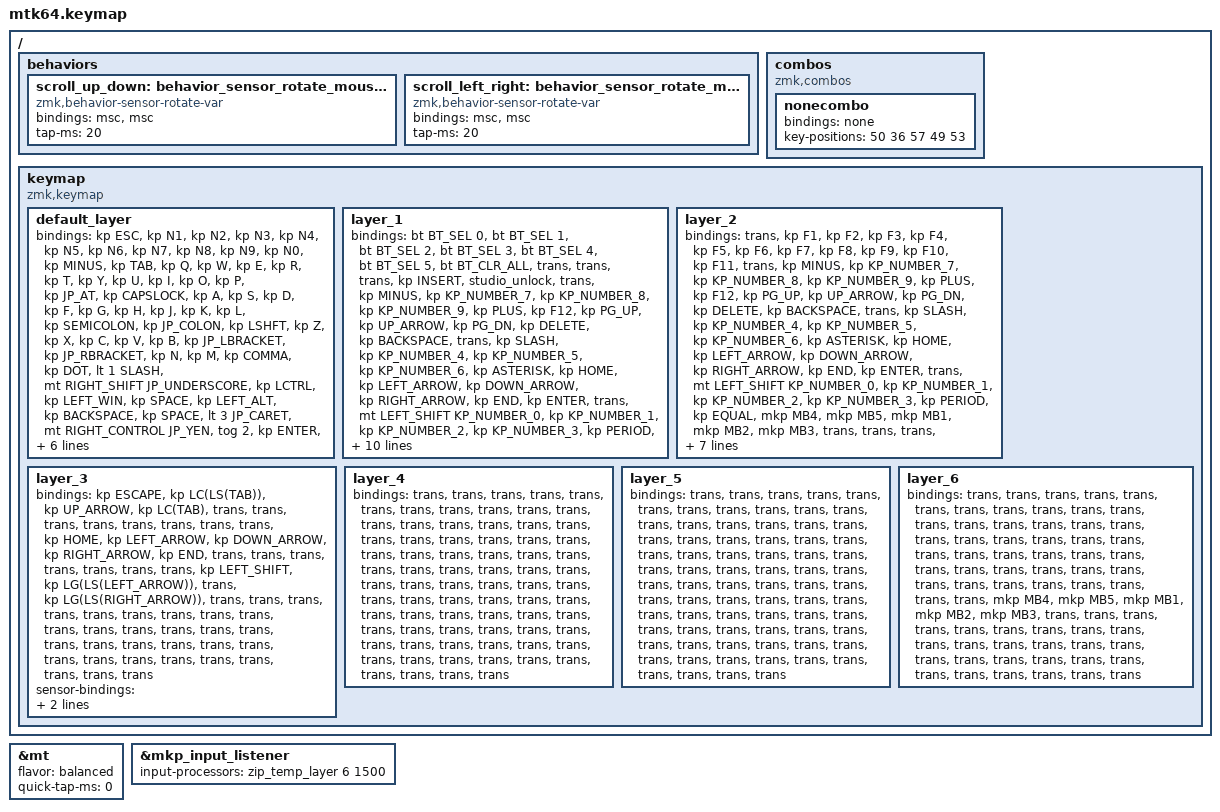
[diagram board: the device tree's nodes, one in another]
#include <input/processors.dtsi>
#include <behaviors.dtsi>
#include <dt-bindings/zmk/bt.h>
#include <dt-bindings/zmk/keys.h>
#include <dt-bindings/zmk/pointing.h>
#include "keycode_japanese.h"

// スクロール量の設定

#define ZMK_POINTING_DEFAULT_SCRL_VAL 100

// OS設定を日本語キーボードのまま使用するための変換定義

#define JP_DQUOTE       AT                // "
#define JP_AMPERSAND    CARET             // &
#define JP_QUOTE        AMPERSAND         // '
#define JP_EQUAL        UNDER             // =
#define JP_CARET        EQUAL             // ^
#define JP_YEN          0x89              // ¥
#define JP_PLUS         COLON             // +
#define JP_TILDE        PLUS              // ~
#define JP_PIPE         LS(0x89)          // |
#define JP_AT           LEFT_BRACKET      // @
#define JP_COLON        SINGLE_QUOTE      // :
#define JP_ASTERISK     DOUBLE_QUOTES     // *
#define JP_BACKQUOTE    LEFT_BRACE        // `
#define JP_UNDERSCORE   LS(0x87)          // _
#define JP_LBRACKET     RIGHT_BRACKET     // [
#define JP_RBRACKET     BACKSLASH         // ]
#define JP_LPAREN       ASTERISK          // (
#define JP_RPAREN       LEFT_PARENTHESIS  // )
#define JP_LBRACE       RIGHT_BRACE       // {
#define JP_RBRACE       PIPE              // }
#define JP_KANA         LANGUAGE_1        // かな
#define JP_EISU         LANGUAGE_2        // 英数
#define JP_HANZEN       GRAVE             // 半角/全角

&mt {
    flavor = "balanced";
    quick-tap-ms = <0>;
};

&mkp_input_listener { input-processors = <&zip_temp_layer 6 1500>; };

/ {
    behaviors {
        // 垂直スクロール用のbehaviorの設定

        scroll_up_down: behavior_sensor_rotate_mouse_wheel_up_down {
            compatible = "zmk,behavior-sensor-rotate-var";
            #sensor-binding-cells = <2>;
            bindings = <&msc>, <&msc>;

            tap-ms = <20>; // スクロールのタップ時間
        };

        // 水平スクロール用のbehaviorの設定

        scroll_left_right: behavior_sensor_rotate_mouse_wheel_left_right {
            compatible = "zmk,behavior-sensor-rotate-var";
            #sensor-binding-cells = <2>;
            bindings = <&msc>, <&msc>;

            tap-ms = <20>; // スクロールのタップ時間
        };
    };
};

/ {
    combos {
        compatible = "zmk,combos";

        nonecombo {
            bindings = <&none>;
            key-positions = <50 36 57 49 53>;
        };
    };

    keymap {
        compatible = "zmk,keymap";

        default_layer {
            bindings = <
&kp ESC  &kp N1  &kp N2  &kp N3  &kp N4  &kp N5  &kp N6  &kp N7  &kp N8  &kp N9  &kp N0  &kp MINUS  &kp TAB  &kp Q  &kp W  &kp E  &kp R  &kp T  &kp Y  &kp U  &kp I  &kp O  &kp P  &kp JP_AT  &kp CAPSLOCK  &kp A  &kp S  &kp D  &kp F  &kp G  &kp H  &kp J  &kp K  &kp L  &kp SEMICOLON  &kp JP_COLON  &kp LSHFT  &kp Z  &kp X  &kp C  &kp V  &kp B  &kp JP_LBRACKET  &kp JP_RBRACKET  &kp N  &kp M  &kp COMMA  &kp DOT  &lt 1 SLASH  &mt RIGHT_SHIFT JP_UNDERSCORE  &kp LCTRL  &kp LEFT_WIN  &kp SPACE  &kp LEFT_ALT  &kp BACKSPACE  &kp SPACE  &lt 3 JP_CARET  &mt RIGHT_CONTROL JP_YEN  &tog 2  &kp ENTER  &lt 3 JP_HANZEN  &kp ENTER  &kp ENTER  &tog 2  &mo 1  &mo 2  &mo 1  &mo 2  &mo 3  &mo 1  &mo 2  &mo 3  &mo 1  &mo 2  &mo 3
            >;

            sensor-bindings = <
                &inc_dec_kp LEFT_ARROW RIGHT_ARROW
                &inc_dec_kp UP_ARROW   DOWN_ARROW
            >;
        };

        layer_1 {
            bindings = <
&bt BT_SEL 0  &bt BT_SEL 1  &bt BT_SEL 2  &bt BT_SEL 3  &bt BT_SEL 4  &bt BT_SEL 5  &bt BT_CLR_ALL  &trans  &trans  &trans  &kp INSERT  &studio_unlock  &trans  &kp MINUS  &kp KP_NUMBER_7  &kp KP_NUMBER_8  &kp KP_NUMBER_9  &kp PLUS  &kp F12  &kp PG_UP  &kp UP_ARROW  &kp PG_DN  &kp DELETE  &kp BACKSPACE  &trans  &kp SLASH  &kp KP_NUMBER_4  &kp KP_NUMBER_5  &kp KP_NUMBER_6  &kp ASTERISK  &kp HOME  &kp LEFT_ARROW  &kp DOWN_ARROW  &kp RIGHT_ARROW  &kp END  &kp ENTER  &trans  &mt LEFT_SHIFT KP_NUMBER_0  &kp KP_NUMBER_1  &kp KP_NUMBER_2  &kp KP_NUMBER_3  &kp PERIOD  &kp EQUAL  &mkp MB4  &mkp MB5  &mkp MB1  &mkp MB2  &mkp MB3  &trans  &trans  &trans  &trans  &trans  &trans  &kp DELETE  &trans  &trans  &kp PRINTSCREEN  &trans  &trans  &trans  &trans  &trans  &trans  &trans  &trans  &trans  &trans  &trans  &trans  &trans  &trans  &trans  &trans  &trans
            >;

            sensor-bindings =
                <&scroll_left_right SCRL_LEFT SCRL_RIGHT>,
                <&scroll_up_down SCRL_UP SCRL_DOWN>;
        };

        layer_2 {
            bindings = <
&trans  &kp F1  &kp F2  &kp F3  &kp F4  &kp F5  &kp F6  &kp F7  &kp F8  &kp F9  &kp F10  &kp F11  &trans  &kp MINUS  &kp KP_NUMBER_7  &kp KP_NUMBER_8  &kp KP_NUMBER_9  &kp PLUS  &kp F12  &kp PG_UP  &kp UP_ARROW  &kp PG_DN  &kp DELETE  &kp BACKSPACE  &trans  &kp SLASH  &kp KP_NUMBER_4  &kp KP_NUMBER_5  &kp KP_NUMBER_6  &kp ASTERISK  &kp HOME  &kp LEFT_ARROW  &kp DOWN_ARROW  &kp RIGHT_ARROW  &kp END  &kp ENTER  &trans  &mt LEFT_SHIFT KP_NUMBER_0  &kp KP_NUMBER_1  &kp KP_NUMBER_2  &kp KP_NUMBER_3  &kp PERIOD  &kp EQUAL  &mkp MB4  &mkp MB5  &mkp MB1  &mkp MB2  &mkp MB3  &trans  &trans  &trans  &trans  &trans  &trans  &trans  &trans  &trans  &kp PRINTSCREEN  &trans  &trans  &trans  &trans  &trans  &trans  &trans  &trans  &trans  &trans  &trans  &trans  &trans  &trans  &trans  &trans  &trans
            >;

            sensor-bindings = <
                &inc_dec_kp TAB LS(TAB) 
                &inc_dec_kp PG_UP PG_DN
            >;
        };

        layer_3 {
            bindings = <
&kp ESCAPE  &kp LC(LS(TAB))  &kp UP_ARROW  &kp LC(TAB)  &trans  &trans  &trans  &trans  &trans  &trans  &trans  &trans  &kp HOME  &kp LEFT_ARROW  &kp DOWN_ARROW  &kp RIGHT_ARROW  &kp END  &trans  &trans  &trans  &trans  &trans  &trans  &trans  &kp LEFT_SHIFT  &kp LG(LS(LEFT_ARROW))  &trans  &kp LG(LS(RIGHT_ARROW))  &trans  &trans  &trans  &trans  &trans  &trans  &trans  &trans  &trans  &trans  &trans  &trans  &trans  &trans  &trans  &trans  &trans  &trans  &trans  &trans  &trans  &trans  &trans  &trans  &trans  &trans  &trans  &trans  &trans  &trans
            >;

            sensor-bindings = <
                &scroll_left_right SCRL_LEFT SCRL_RIGHT
                &scroll_up_down SCRL_UP SCRL_DOWN
            >;
        };

        layer_4 {
            bindings = <
&trans  &trans  &trans  &trans  &trans  &trans  &trans  &trans  &trans  &trans  &trans  &trans  &trans  &trans  &trans  &trans  &trans  &trans  &trans  &trans  &trans  &trans  &trans  &trans  &trans  &trans  &trans  &trans  &trans  &trans  &trans  &trans  &trans  &trans  &trans  &trans  &trans  &trans  &trans  &trans  &trans  &trans  &trans  &trans  &trans  &trans  &trans  &trans  &trans  &trans  &trans  &trans  &trans  &trans  &trans  &trans  &trans  &trans  &trans  &trans  &trans  &trans  &trans  &trans  &trans  &trans  &trans  &trans  &trans  &trans  &trans  &trans  &trans  &trans  &trans
            >;
        };

        layer_5 {
            bindings = <
&trans  &trans  &trans  &trans  &trans  &trans  &trans  &trans  &trans  &trans  &trans  &trans  &trans  &trans  &trans  &trans  &trans  &trans  &trans  &trans  &trans  &trans  &trans  &trans  &trans  &trans  &trans  &trans  &trans  &trans  &trans  &trans  &trans  &trans  &trans  &trans  &trans  &trans  &trans  &trans  &trans  &trans  &trans  &trans  &trans  &trans  &trans  &trans  &trans  &trans  &trans  &trans  &trans  &trans  &trans  &trans  &trans  &trans  &trans  &trans  &trans  &trans  &trans  &trans  &trans  &trans  &trans  &trans  &trans  &trans  &trans  &trans  &trans  &trans  &trans
            >;
        };

        layer_6 {
            bindings = <
&trans  &trans  &trans  &trans  &trans  &trans  &trans  &trans  &trans  &trans  &trans  &trans  &trans  &trans  &trans  &trans  &trans  &trans  &trans  &trans  &trans  &trans  &trans  &trans  &trans  &trans  &trans  &trans  &trans  &trans  &trans  &trans  &trans  &trans  &trans  &trans  &trans  &trans  &trans  &trans  &trans  &trans  &trans  &mkp MB4  &mkp MB5  &mkp MB1  &mkp MB2  &mkp MB3  &trans  &trans  &trans  &trans  &trans  &trans  &trans  &trans  &trans  &trans  &trans  &trans  &trans  &trans  &trans  &trans  &trans  &trans  &trans  &trans  &trans  &trans  &trans  &trans  &trans  &trans  &trans
            >;
        };
    };
};
